# CTSD16_B4_1 register map
Vendor: Texas Instruments
Peripheral module from a debugger description file (folder msp430).
Registers are 16-bit, read-write, reset 0x0 unless marked. A register's access mark holds for its fields unless they carry their own. Offsets are as the file gives them; lines under a group give offsets from that group; [hi:lo] are bit positions; {n}, {i} and the like mark numbered series; 'fields as' and 'values as' point back to an identical list; <NAME> marks a mode.

## CTSD16_B4
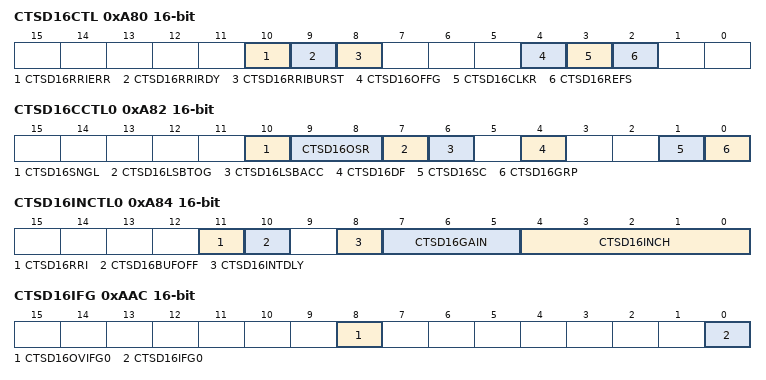
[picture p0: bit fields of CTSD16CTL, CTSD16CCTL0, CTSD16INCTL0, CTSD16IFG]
0xA80 CTSD16CTL — CTSD16 Control Register 0
  [10] CTSD16RRIERR — CTSD16 Rail-to-rail input error
  [9] CTSD16RRIRDY — CTSD16 Rail-to-rail input ready
  [8] CTSD16RRIBURST — Rail-to-rail input charge pump burst mode request
  [4] CTSD16OFFG — CTSD16 clock fault flag
  [3] CTSD16CLKR — CTSD16CLK resistor select
  [2] CTSD16REFS — CTSD16 reference select
0xA82 CTSD16CCTL0 — CTSD16 Channel 0 Control Register
  [10] CTSD16SNGL — CTSD16 Channel Single Conversion Mode
  [9:8] CTSD16OSR — CTSD16 Channel OverSampling Ratio 0
    {v}=CTSD16 Channel OverSampling Ratio {v} (v=0..3)
  [7] CTSD16LSBTOG — CTSD16 LSB toggle
  [6] CTSD16LSBACC — CTSD16 LSB access
  [4] CTSD16DF — CTSD16 Data Format
  [1] CTSD16SC — CTSD16 Start Conversion
  [0] CTSD16GRP — CTSD16 group
0xA84 CTSD16INCTL0 — CTSD16 Channel 0 Input Control Register
  [11] CTSD16RRI — CTSD16 Rail-to-rail input enable
  [10] CTSD16BUFOFF — CTSD16 Controls input buffer
  [8] CTSD16INTDLY — CTSD16 Interrupt Delay after 1.Conversion
  [7:5] CTSD16GAIN — CTSD16 Input Pre-Amplifier Gain Select 0
  [4:0] CTSD16INCH — CTSD16 Input Channel select 0
    {v}=CTSD16 Input Channel select A{v} (v=0..5); 6=CTSD16 Input Channel select Temp; 7=CTSD16 Input Channel select Vcc; 8=CTSD16 Input Channel select VBat; 9=CTSD16 Input Channel select AD0+ / AD0-; 10=CTSD16 Input Channel select AD0+ / VREF; 11=CTSD16 Input Channel select AD1+ / AD1-; 12=CTSD16 Input Channel select AD1+ / VREF; 13=CTSD16 Input Channel select AD2+ / AD2-; 14=CTSD16 Input Channel select AD2+ / VREF; 15=CTSD16 Input Channel select AD3+ / AD3 -; 16=CTSD16 Input Channel select AD3+ / VREF; 17=CTSD16 Input Channel select AD4x - VREF; 18=CTSD16 Input Channel select AD4x - DAC0
0xA86 CTSD16PRE0 access not given reset not defined — CTSD16 Channel 0 Preload Register
0xAAC CTSD16IFG — CTSD16 Interrupt Flag Register
  [8] CTSD16OVIFG0 — CTSD16 Channel 0 Overflow Interrupt Flag
  [0] CTSD16IFG0 — CTSD16 Channel 0 Interrupt Flag
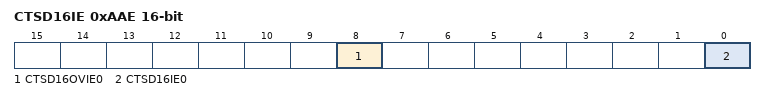
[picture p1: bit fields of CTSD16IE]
0xAAE CTSD16IE — CTSD16 Interrupt Enable Register
  [8] CTSD16OVIE0 — CTSD16 Channel 0 Overflow Interrupt Enable
  [0] CTSD16IE0 — CTSD16 Channel 0 Interrupt Enable
0xAB0 CTSD16IV access not given reset not defined — CTSD16 Interrupt Vector Register
0xAB2 CTSD16MEM0 access not given reset not defined — CTSD16 Channel 0 Conversion Memory
